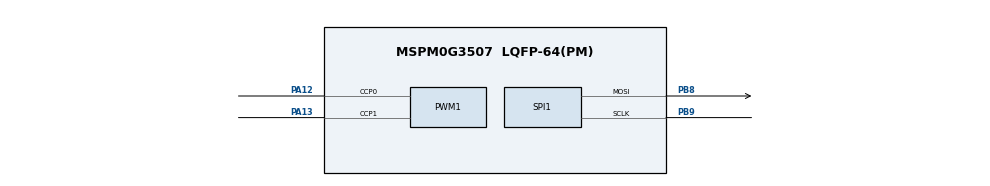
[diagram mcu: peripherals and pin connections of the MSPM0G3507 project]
/**
 * AI AGENTS: Do not edit this file directly. There is no validation or error feedback when
 * editing manually — mistakes will be silent until the file is loaded in SysConfig.
 * Use the SysConfig MCP server instead to make changes with immediate error reporting.
 *
 * These arguments were used when this file was generated. They will be automatically applied on subsequent loads
 * via the GUI or CLI. Run CLI with '--help' for additional information on how to override these arguments.
 * @cliArgs --device "MSPM0G350X" --part "Default" --package "LQFP-64(PM)" --product "mspm0_sdk@2.11.00.07"
 * @v2CliArgs --device "MSPM0G3507" --package "LQFP-64(PM)" --product "mspm0_sdk@2.11.00.07"
 * @versions {"tool":"1.28.0+4696"}
 */

/**
 * Import the modules used in this configuration.
 */
const GPIO   = scripting.addModule("/ti/driverlib/GPIO", {}, false);
const GPIO1  = GPIO.addInstance();
const PWM    = scripting.addModule("/ti/driverlib/PWM", {}, false);
const PWM1   = PWM.addInstance();
const SPI    = scripting.addModule("/ti/driverlib/SPI", {}, false);
const SPI1   = SPI.addInstance();
const SYSCTL = scripting.addModule("/ti/driverlib/SYSCTL");
const UART   = scripting.addModule("/ti/driverlib/UART", {}, false);
const UART1  = UART.addInstance();

/**
 * Write custom configuration values to the imported modules.
 */
GPIO1.$name                          = "DC_MOTOR";
GPIO1.associatedPins.create(8);
GPIO1.associatedPins[0].$name        = "AIN1";
GPIO1.associatedPins[0].assignedPort = "PORTA";
GPIO1.associatedPins[0].assignedPin  = "8";
GPIO1.associatedPins[1].$name        = "AIN2";
GPIO1.associatedPins[1].assignedPort = "PORTA";
GPIO1.associatedPins[1].assignedPin  = "15";
GPIO1.associatedPins[2].$name        = "STBY";
GPIO1.associatedPins[2].assignedPort = "PORTB";
GPIO1.associatedPins[2].assignedPin  = "24";
GPIO1.associatedPins[3].$name        = "BIN1";
GPIO1.associatedPins[3].assignedPort = "PORTB";
GPIO1.associatedPins[3].assignedPin  = "13";
GPIO1.associatedPins[4].$name        = "BIN2";
GPIO1.associatedPins[4].assignedPort = "PORTB";
GPIO1.associatedPins[4].assignedPin  = "12";
GPIO1.associatedPins[5].$name        = "OLED_RES";
GPIO1.associatedPins[5].assignedPort = "PORTB";
GPIO1.associatedPins[5].assignedPin  = "3";
GPIO1.associatedPins[6].$name        = "OLED_DC";
GPIO1.associatedPins[6].assignedPort = "PORTB";
GPIO1.associatedPins[6].assignedPin  = "2";
GPIO1.associatedPins[7].$name        = "OLED_CS";
GPIO1.associatedPins[7].assignedPort = "PORTA";
GPIO1.associatedPins[7].assignedPin  = "27";

const Board = scripting.addModule("/ti/driverlib/Board", {}, false);

PWM1.$name                              = "PWMA";
PWM1.timerCount                         = 3200;
PWM1.peripheral.$assign                 = "TIMG0";
PWM1.peripheral.ccp0Pin.$assign         = "PA12";
PWM1.peripheral.ccp1Pin.$assign         = "PA13";
PWM1.PWM_CHANNEL_0.$name                = "ti_driverlib_pwm_PWMTimerCC0";
PWM1.PWM_CHANNEL_1.$name                = "ti_driverlib_pwm_PWMTimerCC1";
PWM1.ccp0PinConfig.$name                = "ti_driverlib_gpio_GPIOPinGeneric0";
PWM1.ccp0PinConfig.direction            = scripting.forceWrite("OUTPUT");
PWM1.ccp0PinConfig.hideOutputInversion  = scripting.forceWrite(false);
PWM1.ccp0PinConfig.onlyInternalResistor = scripting.forceWrite(false);
PWM1.ccp0PinConfig.passedPeripheralType = scripting.forceWrite("Digital");
PWM1.ccp0PinConfig.enableConfig         = true;
PWM1.ccp1PinConfig.$name                = "ti_driverlib_gpio_GPIOPinGeneric1";
PWM1.ccp1PinConfig.direction            = scripting.forceWrite("OUTPUT");
PWM1.ccp1PinConfig.hideOutputInversion  = scripting.forceWrite(false);
PWM1.ccp1PinConfig.onlyInternalResistor = scripting.forceWrite(false);
PWM1.ccp1PinConfig.passedPeripheralType = scripting.forceWrite("Digital");
PWM1.ccp1PinConfig.enableConfig         = true;

SPI1.$name                              = "OLED_SPI";
SPI1.peripheral.$assign                 = "SPI1";
SPI1.peripheral.sclkPin.$assign         = "PB9";
SPI1.peripheral.mosiPin.$assign         = "PB8";
SPI1.sclkPinConfig.$name                = "ti_driverlib_gpio_GPIOPinGeneric2";
SPI1.sclkPinConfig.direction            = scripting.forceWrite("OUTPUT");
SPI1.sclkPinConfig.onlyInternalResistor = scripting.forceWrite(false);
SPI1.sclkPinConfig.passedPeripheralType = scripting.forceWrite("Digital");
SPI1.mosiPinConfig.$name                = "ti_driverlib_gpio_GPIOPinGeneric3";
SPI1.mosiPinConfig.direction            = scripting.forceWrite("OUTPUT");
SPI1.mosiPinConfig.hideOutputInversion  = scripting.forceWrite(false);
SPI1.mosiPinConfig.onlyInternalResistor = scripting.forceWrite(false);
SPI1.mosiPinConfig.passedPeripheralType = scripting.forceWrite("Digital");
SPI1.misoPinConfig.$name                = "ti_driverlib_gpio_GPIOPinGeneric4";
SPI1.misoPinConfig.onlyInternalResistor = scripting.forceWrite(false);
SPI1.misoPinConfig.passedPeripheralType = scripting.forceWrite("Digital");
SPI1.cs0PinConfig.$name                 = "ti_driverlib_gpio_GPIOPinGeneric5";
SPI1.cs0PinConfig.direction             = scripting.forceWrite("OUTPUT");
SPI1.cs0PinConfig.hideOutputInversion   = scripting.forceWrite(false);
SPI1.cs0PinConfig.onlyInternalResistor  = scripting.forceWrite(false);
SPI1.cs0PinConfig.passedPeripheralType  = scripting.forceWrite("Digital");

SYSCTL.forceDefaultClkConfig = true;

UART1.$name             = "UART_0";
UART1.targetBaudRate    = 115200;
UART1.enabledInterrupts = ["RX"];
UART1.txPinConfig.$name = "ti_driverlib_gpio_GPIOPinGeneric6";
UART1.rxPinConfig.$name = "ti_driverlib_gpio_GPIOPinGeneric7";

/**
 * Pinmux solution for unlocked pins/peripherals. This ensures that minor changes to the automatic solver in a future
 * version of the tool will not impact the pinmux you originally saw.  These lines can be completely deleted in order to
 * re-solve from scratch.
 */
GPIO1.associatedPins[0].pin.$suggestSolution = "PA8";
GPIO1.associatedPins[1].pin.$suggestSolution = "PA15";
GPIO1.associatedPins[2].pin.$suggestSolution = "PB24";
GPIO1.associatedPins[3].pin.$suggestSolution = "PB13";
GPIO1.associatedPins[4].pin.$suggestSolution = "PB12";
GPIO1.associatedPins[5].pin.$suggestSolution = "PB3";
GPIO1.associatedPins[6].pin.$suggestSolution = "PB2";
GPIO1.associatedPins[7].pin.$suggestSolution = "PA27";
Board.peripheral.$suggestSolution            = "DEBUGSS";
Board.peripheral.swclkPin.$suggestSolution   = "PA20";
Board.peripheral.swdioPin.$suggestSolution   = "PA19";
SPI1.peripheral.misoPin.$suggestSolution     = "PA16";
SPI1.peripheral.cs0Pin.$suggestSolution      = "PA2";
SYSCTL.peripheral.$suggestSolution           = "SYSCTL";
UART1.peripheral.$suggestSolution            = "UART0";
UART1.peripheral.rxPin.$suggestSolution      = "PA1";
UART1.peripheral.txPin.$suggestSolution      = "PA0";
